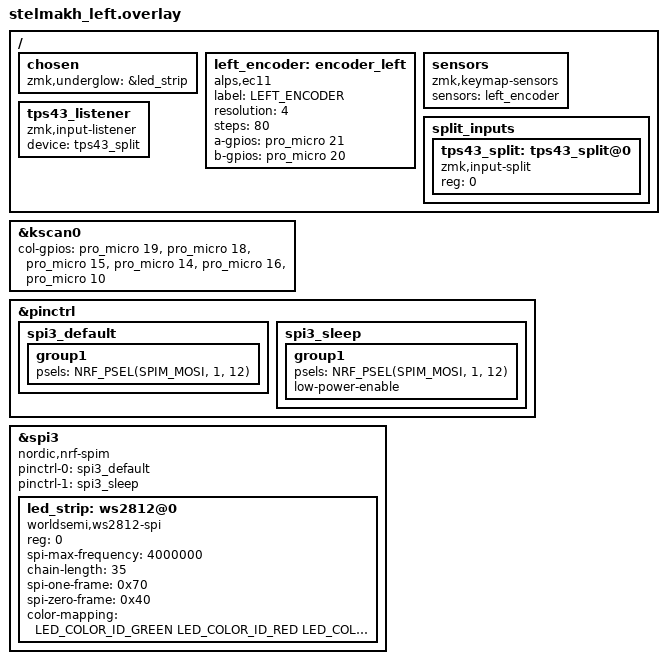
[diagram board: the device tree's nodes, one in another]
#include <dt-bindings/gpio/gpio.h>
#include <dt-bindings/led/led.h>
#include <dt-bindings/pinctrl/nrf-pinctrl.h>
#include "stelmakh.dtsi"

&kscan0 {
    col-gpios
        = <&pro_micro 19 GPIO_ACTIVE_HIGH>
        , <&pro_micro 18 GPIO_ACTIVE_HIGH>
        , <&pro_micro 15 GPIO_ACTIVE_HIGH>
        , <&pro_micro 14 GPIO_ACTIVE_HIGH>
        , <&pro_micro 16 GPIO_ACTIVE_HIGH>
        , <&pro_micro 10 GPIO_ACTIVE_HIGH>
        ;
};

// ─────────────────────────────────────────────────────────────
// WS2812 RGB Underglow
// Пин данных: P1.12 — взят из stelmakh-pinctrl.dtsi (spi3)
// ─────────────────────────────────────────────────────────────
&pinctrl {
    spi3_default: spi3_default {
        group1 {
            psels = <NRF_PSEL(SPIM_MOSI, 1, 12)>;
        };
    };

    spi3_sleep: spi3_sleep {
        group1 {
            psels = <NRF_PSEL(SPIM_MOSI, 1, 12)>;
            low-power-enable;
        };
    };
};

&spi3 {
    compatible = "nordic,nrf-spim";
    status = "okay";

    pinctrl-0 = <&spi3_default>;
    pinctrl-1 = <&spi3_sleep>;
    pinctrl-names = "default", "sleep";

    led_strip: ws2812@0 {
        compatible = "worldsemi,ws2812-spi";
        reg = <0>;
        spi-max-frequency = <4000000>;
        chain-length = <35>; /* измени на реальное кол-во светодиодов */
        spi-one-frame = <0x70>;
        spi-zero-frame = <0x40>;
        color-mapping = <LED_COLOR_ID_GREEN
                         LED_COLOR_ID_RED
                         LED_COLOR_ID_BLUE>;
    };
};

/ {
    chosen {
        zmk,underglow = &led_strip;
    };

    left_encoder: encoder_left {
        status = "okay";
        compatible = "alps,ec11";
        label = "LEFT_ENCODER";
        resolution = <4>;
        steps = <80>;
        a-gpios = <&pro_micro 21 (GPIO_ACTIVE_HIGH | GPIO_PULL_UP)>;
        b-gpios = <&pro_micro 20 (GPIO_ACTIVE_HIGH | GPIO_PULL_UP)>;
    };

    sensors {
        compatible = "zmk,keymap-sensors";
        sensors = <&left_encoder>;
    };

    split_inputs {
        #address-cells = <1>;
        #size-cells = <0>;
        tps43_split: tps43_split@0 {
            compatible = "zmk,input-split";
            reg = <0>;
        };
    };

    tps43_listener: tps43_listener {
        compatible = "zmk,input-listener";
        device = <&tps43_split>;
        status = "okay";
    };
};
